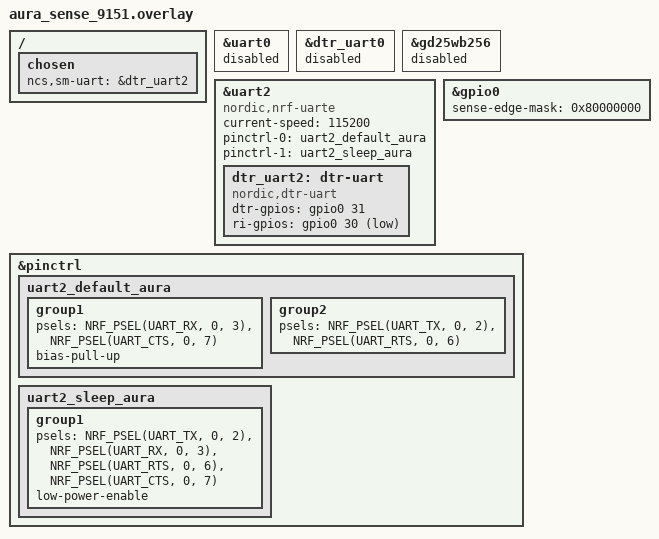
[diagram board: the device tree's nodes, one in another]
/*
 * Aura Sense Pro - onboard nRF9151 (U3) Serial Modem UART, with DTR/RI.
 *
 * Pins traced from aura-sense-hw-pro.kicad_pcb by NET -> PAD (U3 = nRF9151):
 *   nRF9151 RXD = P0.03 (U3 pad 59)  <- nRF54L15 TXD P0.00
 *   nRF9151 TXD = P0.02 (U3 pad 58)  -> nRF54L15 RXD P0.01
 *   nRF9151 RTS = P0.06 (U3 pad 63)  -> nRF54L15 CTS P0.03
 *   nRF9151 CTS = P0.07 (U3 pad 64)  <- nRF54L15 RTS P0.02
 *   nRF9151 DTR = P0.31 (senses)     <- host P1.02 (PCB net /LTE/DTR, R62+TP13)
 *   nRF9151 RI  = P0.30 (drives)     -> host P0.04 (PCB net /LTE/RING, TP12)
 * 115200 8N1, matching host uart30 in the FW board DTS.
 *
 * The AT UART is wrapped in a nordic,dtr-uart node so SLM's AT#XSLEEP works:
 * with DTR asserted the modem UART is powered and answers AT; when the host
 * deasserts DTR the driver powers the UART down (the low-power state XSLEEP
 * enters), and the modem raises RI when it has data.
 *
 * DTR polarity is ACTIVE_HIGH (like the nRF9151 DK reference overlay), NOT the
 * external-mcu overlay's ACTIVE_LOW: on this board HIGH = asserted = awake.
 * With the pull-up the line idles asserted, so the modem stays awake unless the
 * host actively drives it low -- avoids the accidental System-OFF/brick we hit.
 */

/ {
	chosen {
		ncs,sm-uart = &dtr_uart2;
	};
};

/* Disable the DK's default AT UART and its DTR wrapper. */
&uart0     { status = "disabled"; };
&dtr_uart0 { status = "disabled"; };

/* The DK's external SPI-NOR (gd25wb256) is NOT fitted on the Aura board. */
&gd25wb256 { status = "disabled"; };

&uart2 {
	compatible = "nordic,nrf-uarte";
	current-speed = <115200>;
	/* HW flow control OFF (must match host uart30). The AT link was only ever
	 * validated HWFC-off; with HWFC on, the host's uart_poll_out blocks forever
	 * on CTS whenever the modem hasn't asserted RTS -> "AT hangs". Re-enable on
	 * BOTH sides together only after the plain link + DTR sleep/wake are
	 * confirmed working. RTS/CTS pins stay routed by pinctrl but unused. */
	/* hw-flow-control; */   /* modem P0.06=RTS / P0.07=CTS <-> host P0.02/P0.03 */
	status = "okay";
	pinctrl-0 = <&uart2_default_aura>;
	pinctrl-1 = <&uart2_sleep_aura>;
	pinctrl-names = "default", "sleep";

	dtr_uart2: dtr-uart {
		compatible = "nordic,dtr-uart";
		dtr-gpios = <&gpio0 31 (GPIO_PULL_UP | GPIO_ACTIVE_HIGH)>; /* P0.31: HIGH=asserted=awake, matches nRF9151 DK ref (NOT external-mcu's active-low) */
		ri-gpios  = <&gpio0 30 GPIO_ACTIVE_LOW>;                 /* P0.30 */
		status = "okay";
	};
};

&gpio0 {
	status = "okay";
	/* PORT event on DTR (P0.31) so DTR wake is detected from low power. */
	sense-edge-mask = <0x80000000>;
};

&pinctrl {
	uart2_default_aura: uart2_default_aura {
		group1 {
			psels = <NRF_PSEL(UART_RX,  0, 3)>,   /* nRF91 RXD = P0.03 */
				<NRF_PSEL(UART_CTS, 0, 7)>;   /* nRF91 CTS = P0.07 */
			bias-pull-up;
		};
		group2 {
			psels = <NRF_PSEL(UART_TX,  0, 2)>,   /* nRF91 TXD = P0.02 */
				<NRF_PSEL(UART_RTS, 0, 6)>;   /* nRF91 RTS = P0.06 */
		};
	};

	uart2_sleep_aura: uart2_sleep_aura {
		group1 {
			psels = <NRF_PSEL(UART_TX,  0, 2)>, <NRF_PSEL(UART_RX,  0, 3)>,
				<NRF_PSEL(UART_RTS, 0, 6)>, <NRF_PSEL(UART_CTS, 0, 7)>;
			low-power-enable;
		};
	};
};
